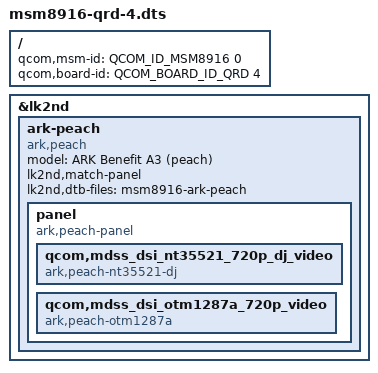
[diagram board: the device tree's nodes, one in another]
// SPDX-License-Identifier: BSD-3-Clause

#include <skeleton64.dtsi>
#include <lk2nd.dtsi>

/ {
	qcom,msm-id = <QCOM_ID_MSM8916 0>;
	qcom,board-id = <QCOM_BOARD_ID_QRD 4>;
};

&lk2nd {
	ark-peach {
		model = "ARK Benefit A3 (peach)";
		compatible = "ark,peach";
		lk2nd,match-panel;

		lk2nd,dtb-files = "msm8916-ark-peach";

		panel {
			compatible = "ark,peach-panel", "lk2nd,panel";

			qcom,mdss_dsi_nt35521_720p_dj_video {
				compatible = "ark,peach-nt35521-dj";
			};
			qcom,mdss_dsi_otm1287a_720p_video {
				compatible = "ark,peach-otm1287a";
			};
		};
	};
};
